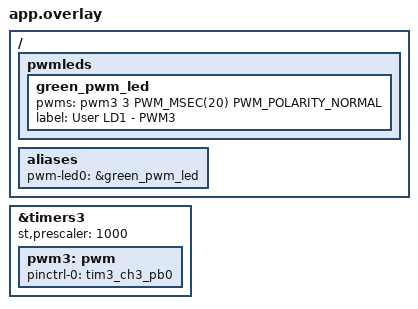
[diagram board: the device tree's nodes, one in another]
/ {
	pwmleds {
		green_pwm_led: green_pwm_led {
			pwms = <&pwm3 3 PWM_MSEC(20) PWM_POLARITY_NORMAL>;
			label = "User LD1 - PWM3";
		};
	};

	aliases {
		pwm-led0 = &green_pwm_led;
	};
};

&timers3 {
	st,prescaler = <1000>;
	status = "okay";

	pwm3: pwm {
		status = "okay";
		pinctrl-0 = <&tim3_ch3_pb0>;
		pinctrl-names = "default";
	};
};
